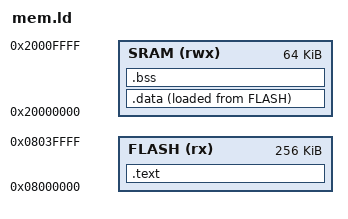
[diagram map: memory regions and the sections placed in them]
ENTRY(ResetHandler)

MEMORY
{
    FLASH (rx) : ORIGIN = 0x08000000, LENGTH = 256K
    SRAM (rwx) : ORIGIN = 0x20000000, LENGTH = 64K
}

SECTIONS
{
    .text :
    {
        *(.text)
        _etext = .;
    } > FLASH

    .data :
    {
        _sdata = .;
        *(.data)
        _edata = .;
    } > SRAM AT> FLASH

    .bss :
    {
        _sbss = .;
        *(.bss)
        _ebss = .;
    } > SRAM
}




